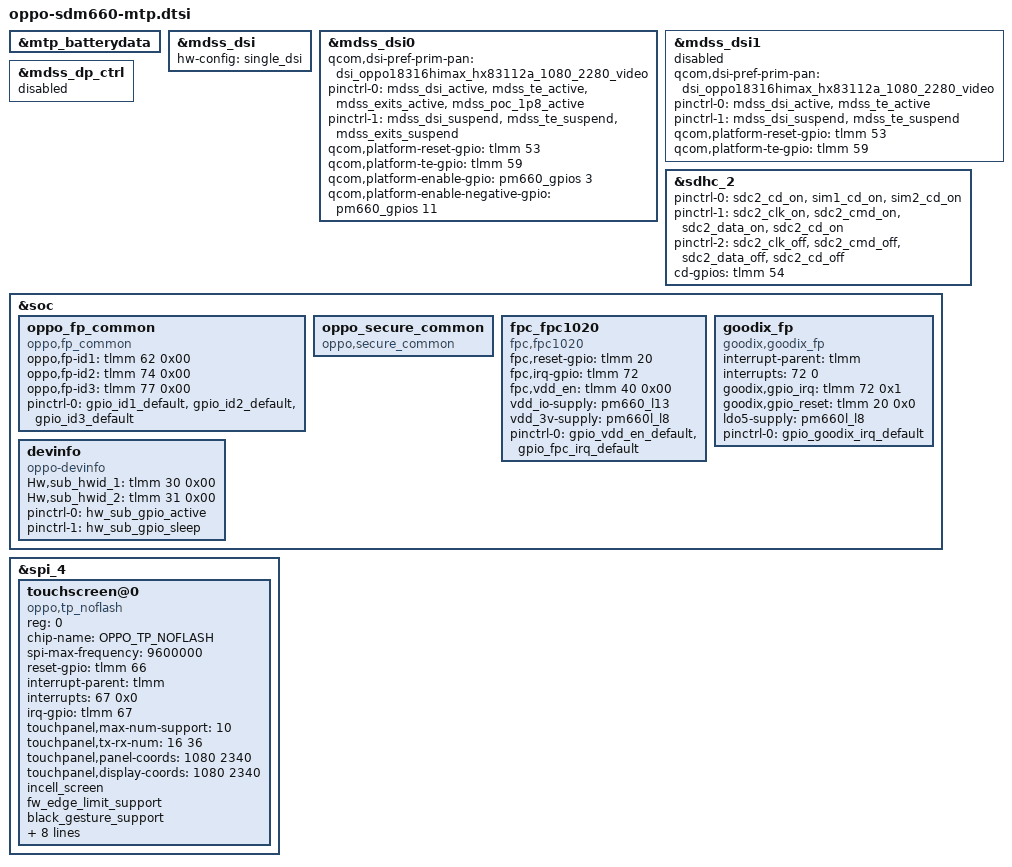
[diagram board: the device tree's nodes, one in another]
/* Copyright shits here */

&mtp_batterydata {
	#include "oppo-fg-gen3-batterydata-atl-3000mah.dtsi"
};

&mdss_dsi {
	hw-config = "single_dsi";
};

&mdss_dsi0 {
	qcom,dsi-pref-prim-pan = <&dsi_oppo18316himax_hx83112a_1080_2280_video>;
	pinctrl-names = "mdss_default", "mdss_sleep";
	pinctrl-0 = <&mdss_dsi_active &mdss_te_active &mdss_exits_active &mdss_poc_1p8_active>;
	pinctrl-1 = <&mdss_dsi_suspend &mdss_te_suspend &mdss_exits_suspend>;
	qcom,platform-reset-gpio = <&tlmm 53 0>;
	qcom,platform-te-gpio = <&tlmm 59 0>;
	qcom,platform-enable-gpio = <&pm660_gpios 3 0>; /* GPIO_01 LCD_5V_ENP */
	qcom,platform-enable-negative-gpio = <&pm660_gpios 11 0>; /* GPIO_11 LCD_5V_ENN */
};

&mdss_dsi1 {
	status = "disabled";
	qcom,dsi-pref-prim-pan = <&dsi_oppo18316himax_hx83112a_1080_2280_video>;
	pinctrl-names = "mdss_default", "mdss_sleep";
	pinctrl-0 = <&mdss_dsi_active &mdss_te_active>;
	pinctrl-1 = <&mdss_dsi_suspend &mdss_te_suspend>;
	qcom,platform-reset-gpio = <&tlmm 53 0>;
	qcom,platform-te-gpio = <&tlmm 59 0>;
};

&mdss_dp_ctrl {
	status = "disabled";
};

&sdhc_2 {
	pinctrl-names = "default", "active", "sleep";
	pinctrl-0 = <&sdc2_cd_on &sim1_cd_on &sim2_cd_on>;
	pinctrl-1 = <&sdc2_clk_on  &sdc2_cmd_on &sdc2_data_on &sdc2_cd_on>;
	pinctrl-2 = <&sdc2_clk_off &sdc2_cmd_off &sdc2_data_off &sdc2_cd_off>;
	cd-gpios = <&tlmm 54 0x0>;
};

&soc {
	oppo_fp_common {
		compatible = "oppo,fp_common"; // Manufacturer and Model
		oppo,fp-id1 = <&tlmm 62 0x00>;
		oppo,fp-id2 = <&tlmm 74 0x00>;
		oppo,fp-id3 = <&tlmm 77 0x00>;
		pinctrl-names = "default";
		pinctrl-0 = <&gpio_id1_default &gpio_id2_default &gpio_id3_default>;
	};

	oppo_secure_common {
		compatible = "oppo,secure_common"; // Manufacturer and Model
	};

	fpc_fpc1020 {
		compatible = "fpc,fpc1020"; // Manufacturer and Model
		fpc,reset-gpio = <&tlmm 20 0x00>;
		fpc,irq-gpio = <&tlmm 72 0x00>;
		fpc,vdd_en = <&tlmm 40 0x00>;
		vdd_io-supply = <&pm660_l13>; // 1.8V
		vdd_3v-supply = <&pm660l_l8>; // 3V
		pinctrl-names = "default";
		pinctrl-0 = <&gpio_vdd_en_default &gpio_fpc_irq_default>;
	};

	goodix_fp {
		compatible = "goodix,goodix_fp";
		interrupt-parent = <&tlmm>;
		interrupts = <72 0>;
		goodix,gpio_irq = <&tlmm 72 0x1>;
		goodix,gpio_reset = <&tlmm 20 0x0>;
		ldo5-supply = <&pm660l_l8>; // pm660l_l8 for goodix_fp
		pinctrl-names = "default";
		pinctrl-0 = <&gpio_goodix_irq_default>;
	};

	devinfo {
		compatible = "oppo-devinfo";
		Hw,sub_hwid_1 = <&tlmm 30 0x00>;
		Hw,sub_hwid_2 = <&tlmm 31 0x00>;
		pinctrl-names = "default","hw_sub_gpio_sleep";
		pinctrl-0 = <&hw_sub_gpio_active>;
		pinctrl-1 = <&hw_sub_gpio_sleep>;
	};
};

&spi_4 {
	/* Novatek device tree node */
	status = "ok";
	touchscreen@0 {
		compatible = "oppo,tp_noflash";
		reg = <0>;
		chip-name = "OPPO_TP_NOFLASH";
		status = "ok";
		spi-max-frequency = <9600000>; //4800000,9600000,15000000,19200000
		reset-gpio = <&tlmm 66 0x00>;
		interrupt-parent = <&tlmm>;
		interrupts = <67 0x0>;
		irq-gpio = <&tlmm 67 0x2002>;
		touchpanel,max-num-support = <10>;
		touchpanel,tx-rx-num = <16 36>;
		touchpanel,panel-coords = <1080 2340>;
		touchpanel,display-coords = <1080 2340>;
		incell_screen;
		fw_edge_limit_support;
		black_gesture_support;
		charger_pump_support;
		esd_handle_support;
		game_switch_support;
		black_gesture_test_support;
		noflash_support;
		smart_gesture_support;
		lcd_trigger_load_tp_fw_support;

		/*
		 * Virtual Key Config:
		 * 1:touchpanel,button-type: <virtualkey_type  supportted_button-map>
		 * virtualkey_type:
		 * Type 1: using board_properties
		 * Type 2: using same IC (button zone&& touch zone are seprate)
		 * Type 3: using diffrent IC (button zone&& touch zone are seprate)
		 * Type 4: No need of virtual key process
		 * supportted_button-map:select|menu|home|back
		 *
		 * 2:touchpanel,button-map
		 * type (X1,Y1)(X2,Y2)(X3,Y3)(Width_X,Hight_Y)--Only when button-type is 0
		 */
		touchpanel,button-type = <4>;
	};
};
